# CH32H41X register map
Vendor: WCH Ltd.; File version: 1.2
Registers are 32-bit, read-write, reset 0x0 unless marked. A register's access mark holds for its fields unless they carry their own. Offsets are from the block's base; [hi:lo] are bit positions; {n}, {i} and the like mark numbered series; 'fields as' and 'values as' point back to an identical list.

## FLASH
Base 0x40022000
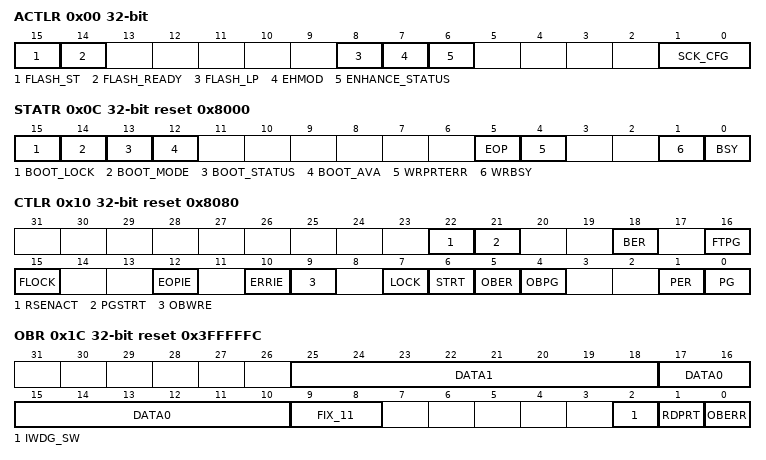
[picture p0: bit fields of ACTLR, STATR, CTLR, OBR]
0x00 ACTLR access per field — Access control register
  [15] FLASH_ST ro — FLASH Low Power Status Indicator Bits
  [14] FLASH_READY ro — flash ready indicator
  [8] FLASH_LP rw — FLASH Low Power Mode Control Bit
  [7] EHMOD rw — flash enhanced read mode control bit
  [6] ENHANCE_STATUS ro — Enhanced Status
  [1:0] SCK_CFG rw — Waiting Status
0x04 KEYR wo — Flash key register
  [31:0] KEYR — FPEC key
0x08 OBKEYR wo — Flash option key register
  [31:0] OBTKEY — Option byte key
0x0C STATR access per field reset 0x8000 — Status register
  [15] BOOT_LOCK rw
  [14] BOOT_MODE rw
  [13] BOOT_STATUS ro
  [12] BOOT_AVA ro
  [5] EOP rw — End of operation
  [4] WRPRTERR rw — Write protection error
  [1] WRBSY ro — Quick page programming
  [0] BSY ro — Busy
0x10 CTLR reset 0x8080 — Control register
  [22] RSENACT — Reset Flash Enhance read mode
  [21] PGSTRT — Page Programming Start
  [18] BER — Block Erase
  [16] FTPG — Fast programming
  [15] FLOCK — Fast programmable lock
  [12] EOPIE — End of operation interrupt enable
  [10] ERRIE — Error interrupt enable
  [9] OBWRE — Option bytes write enable
  [7] LOCK
  [6] STRT — Start
  [5] OBER — Option byte erase
  [4] OBPG — Option byte programming
  [1] PER — Page Erase
  [0] PG — Programming
0x14 ADDR wo — Flash address register
  [31:0] FAR — Flash Address
0x1C OBR ro reset 0x3FFFFFC — Option byte register
  [25:18] DATA1 — Data byte 1
  [17:10] DATA0 — Data byte 0
  [9:8] FIX_11 — Fixed to 11
  [2] IWDG_SW
  [1] RDPRT — Read protection
  [0] OBERR — Option byte error
0x20 WPR ro — Write protection register
  [31:0] WRP — Write protect
0x24 MODEKEYR wo — Mode select register
  [31:0] MODEKEYR — Mode select
0x2C CFGR0 ro — FLASH configuration register
  [28] DBMODE — FLASH Mode status

## STK — SysTick
Base 0xE000F000
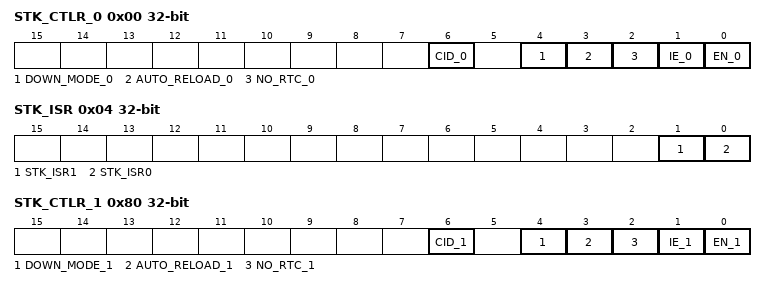
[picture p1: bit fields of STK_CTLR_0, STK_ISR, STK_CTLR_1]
0x00 STK_CTLR_0 — System count control register 0
  [6] CID_0 — Counter 0 allocates a kernel register
  [4] DOWN_MODE_0 — Counting Mode
  [3] AUTO_RELOAD_0 — Auto Reload Count Enable Bit
  [2] NO_RTC_0 — Counter Clock Source Selection Bit
  [1] IE_0 — Counter 0 interrupt enable control bit
  [0] EN_0 — System counter 0 enable control bit
0x04 STK_ISR — System counter interrupt status register
  [1] STK_ISR1 — Systick1 Interrupt Flag
  [0] STK_ISR0 — Systick0 Interrupt Flag
0x08 STK_CNT_0 — System counter 0 count register
  [31:0] CNT_0 — Systick0 counter register, counts are enabled and accumulate/subtract and automatically reload according to configuration
0x10 STK_CMP_0 — System counter 0 comparison register
  [31:0] CMP_0 — Systick0 comparison register for automatic reloading when counting up and comparing when counting down
0x80 STK_CTLR_1 — System count control register 1
  [6] CID_1 — Counter 1 allocates a kernel register
  [4] DOWN_MODE_1 — Counting Mode
  [3] AUTO_RELOAD_1 — Auto Reload Count Enable Bit
  [2] NO_RTC_1 — Counter Clock Source Selection Bit
  [1] IE_1 — Counter 1 interrupt enable control bit
  [0] EN_1 — System counter 1 enable control bit
0x88 STK_CNT_1 — System counter 1 count register
  [31:0] CNT_1 — Systick1 counter register, counts are enabled and accumulate/subtract and automatically reload according to configuration
0x90 STK_CMP_1 — System counter 1 comparison register
  [31:0] CMP_1 — Systick1 comparison register for automatic reloading when counting up and comparing when counting down

## SYSTICK — Dual 32-bit up/down counters shared by V3F + V5F cores with per-counter core ID routing
Base 0xE000F000
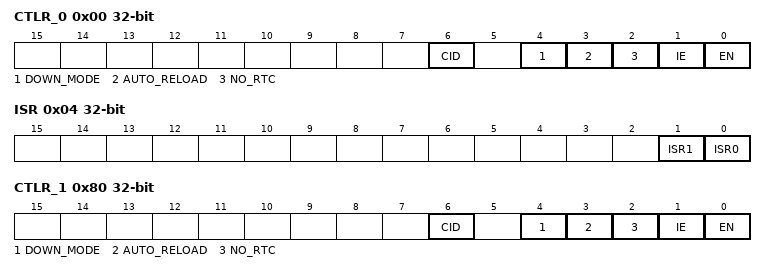
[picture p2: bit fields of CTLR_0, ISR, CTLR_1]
0x00 CTLR_0 — System count control register core 0
  [6] CID — Core ID for distributing interrupts to core 0
  [4] DOWN_MODE — Count mode - 1 down, 0 up
    0=Upcount; 1=Downcount
  [3] AUTO_RELOAD — Auto reload enable
  [2] NO_RTC — Counter clock source selection - 1 HCLK, 0 HCLK/8
    0=HCLK_DIV8 (HCLK/8); 1=HCLK
  [1] IE — Counter interrupt enable
  [0] EN — Counter enable
0x04 ISR — System count interrupt status register
  [1] ISR1 — Systick1 interrupt flag
  [0] ISR0 — Systick0 interrupt flag
0x08 CNT_0 — System counter register core 0
0x10 CMP_0 — System count compare register core 0
0x80 CTLR_1 — System count control register core 1
  [6] CID — Core ID for distributing interrupts to core 1
  [4] DOWN_MODE — Count mode - 1 down, 0 up
    0=Upcount; 1=Downcount
  [3] AUTO_RELOAD — Auto reload enable
  [2] NO_RTC — Counter clock source selection - 1 HCLK, 0 HCLK/8
    0=HCLK_DIV8 (HCLK/8); 1=HCLK
  [1] IE — Counter interrupt enable
  [0] EN — Counter enable
0x88 CNT_1 — System counter register core 1
0x90 CMP_1 — System count compare register core 1

## HSEM
Base 0x0E00C000
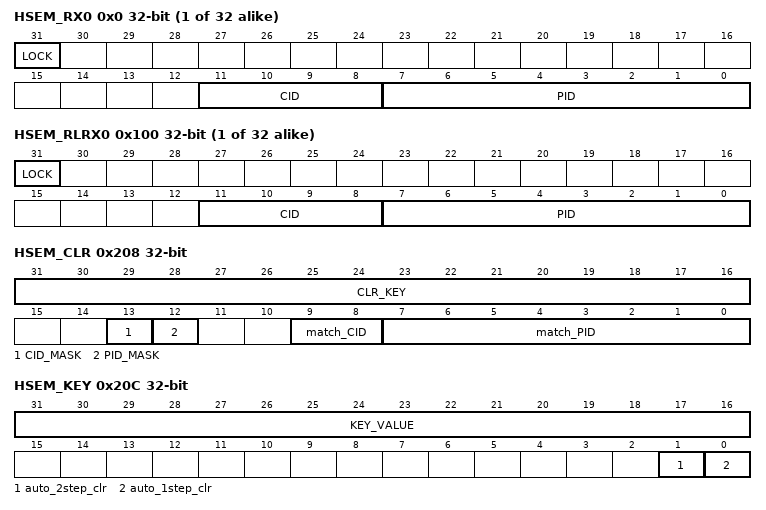
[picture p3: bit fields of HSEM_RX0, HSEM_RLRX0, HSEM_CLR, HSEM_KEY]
{0x0+4i} HSEM_RX{i} (i=0..31) — HSEM register HSEM_RX0 HSEM_RX31
  [31] LOCK — Lock indication
  [11:8] CID — Semaphore CID
  [7:0] PID — Semaphore ProcessID
{0x100+4i} HSEM_RLRX{i} ro (i=0..31) — HSEM Read lock register
  fields as HSEM_RX0
0x200 HSEM_LSE ro — HSEM lock status register
  [31:0] HSEM_LSE — HSEM channel lock status registers to obtain the lock status of 32 channels
0x208 HSEM_CLR wo — HSEM Unlock Register
  [31:16] CLR_KEY — Unlock keywords, the operation is valid when the write data is equal to the matching keyword, otherwise it is invalid. The key value is 0x5AA5
  [13] CID_MASK — CID Matching Shielding
  [12] PID_MASK — PID Matching Shielding
  [9:8] match_CID — It is used to match the unlocked CID value and compare it with the CID value of each locked channel
  [7:0] match_PID — It is used to match the unlocked PID value and compare it with the PID value of each locked channel
0x20C HSEM_KEY access per field — HSEM unlocks the keyword register
  [31:16] KEY_VALUE ro — Unlock keywords, which are used to match unlock method keyword comparisons.
  [1] auto_2step_clr rw — When the channel is locked in 2step mode, the corresponding channel interrupt status bit is automatically cleared.
  [0] auto_1step_clr rw — When the channel is locked in 1step mode, the corresponding channel interrupt status bit is automatically cleared.
0x300 HSEM_IER — HSEM interrupt enable register
  [31:0] HSEM_IER — HSEM channel interrupt enable register, kernel private register, set to 1 when the corresponding channel is unlocked by other cores to allow interrupts. Interaction with HSEM_ISR registers can produce interrupts
0x308 HSEM_ISR — HSEM interrupt status register
  fields as HSEM_IER
0x310 HSEM_ISM ro — HSEM interrupt mask register
  [31:0] HSEM_ISM — HSEM channel lock status registers to obtain the lock status of 32 channels
0x318 HSEM_LSM ro — HSEM Lock Status Mask Register
  fields as HSEM_LSE
